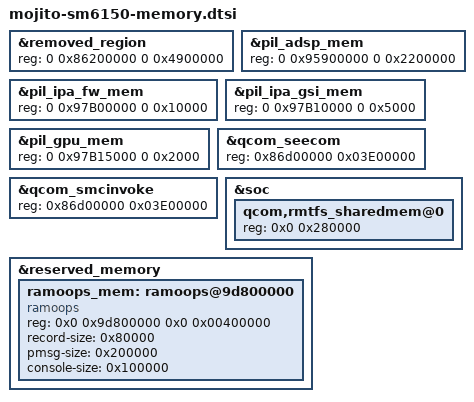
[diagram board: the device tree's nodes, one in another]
/*
 * Copyright (c) 2019, The Linux Foundation. All rights reserved.
 * Copyright (C) 2021 XiaoMi, Inc.
 *
 * This program is free software; you can redistribute it and/or modify
 * it under the terms of the GNU General Public License version 2 and
 * only version 2 as published by the Free Software Foundation.
 *
 * This program is distributed in the hope that it will be useful,
 * but WITHOUT ANY WARRANTY; without even the implied warranty of
 * MERCHANTABILITY or FITNESS FOR A PARTICULAR PURPOSE.  See the
 * GNU General Public License for more details.
 */

&removed_region {
	reg = <0 0x86200000 0 0x4900000>;
};

&pil_adsp_mem {
	reg = <0 0x95900000 0 0x2200000>;
};

&pil_ipa_fw_mem {
	reg = <0 0x97B00000 0 0x10000>;
};

&pil_ipa_gsi_mem {
	reg = <0 0x97B10000 0 0x5000>;
};

&pil_gpu_mem {
	reg = <0 0x97B15000 0 0x2000>;
};

&qcom_seecom {
	reg = <0x86d00000 0x03E00000>;
};

&qcom_smcinvoke {
	reg = <0x86d00000 0x03E00000>;
};

&soc {
	qcom,rmtfs_sharedmem@0 {
		reg = <0x0 0x280000>;
	};
};

&reserved_memory {
	ramoops_mem: ramoops@9d800000 {
		compatible = "ramoops";
		reg = <0x0 0x9d800000 0x0 0x00400000>;

		record-size = <0x80000>;
		pmsg-size = <0x200000>;
		console-size = <0x100000>;
	};
};
